# R7FA2L1AB register map
Vendor: Renesas Electronics Corporation; Series: RA2L1; File version: 0.50.00
CPU: CM23 r1p0, little endian, MPU, no FPU, VTOR, 2 interrupt priority bits, 32 interrupts
Registers are 8-bit, read-write, reset 0x0 unless marked. A register's access mark holds for its fields unless they carry their own. Offsets are from the block's base; [hi:lo] are bit positions; {n}, {i} and the like mark numbered series; 'fields as' and 'values as' point back to an identical list.

## RTC — Realtime Clock
Base 0x40044000
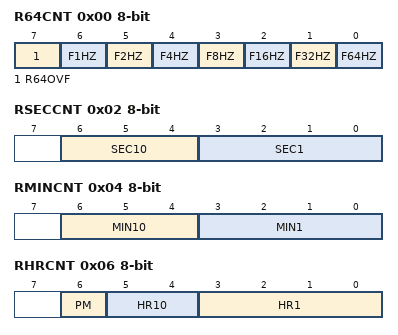
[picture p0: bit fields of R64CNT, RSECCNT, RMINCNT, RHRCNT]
0x00 R64CNT ro reset not defined — 64-Hz Counter
  [7] R64OVF
  [6] F1HZ — This bit indicates the 1-Hz state of the sub-second digit.
  [5] F2HZ — This bit indicates the 2-Hz state of the sub-second digit.
  [4] F4HZ — This bit indicates the 4-Hz state of the sub-second digit.
  [3] F8HZ — This bit indicates the 8-Hz state of the sub-second digit.
  [2] F16HZ — This bit indicates the 16-Hz state of the sub-second digit.
  [1] F32HZ — This bit indicates the 32-Hz state of the sub-second digit.
  [0] F64HZ — This bit indicates the 64-Hz state of the sub-second digit.
{0x2+2i} BCNT{i} (i=0..3) reset not defined — Binary Counter {i}
  [7:0] BCNT — Binary Counter
0x02 RSECCNT reset not defined — Second Counter (in Calendar Count Mode)
  [6:4] SEC10 — 10-Second Count
  [3:0] SEC1 — 1-Second Count
0x04 RMINCNT reset not defined — Minute Counter (in Calendar Count Mode)
  [6:4] MIN10 — 10-Minute Count
  [3:0] MIN1 — 1-Minute Count
0x06 RHRCNT reset not defined — Hour Counter (in Calendar Count Mode)
  [6] PM — AM/PM select for time counter setting.
    0=AM; 1=PM
  [5:4] HR10 — 10-Hour Count
  [3:0] HR1 — 1-Hour Count
0x08 RWKCNT reset not defined — Day-of-Week Counter (in Calendar Count Mode)
  [2:0] DAYW — Day-of-Week Counting
    0=Sunday; 1=Monday; 2=Tuesday; 3=Wednesday; 4=Thursday; 5=Friday; 6=Saturday; 7=Setting prohibited
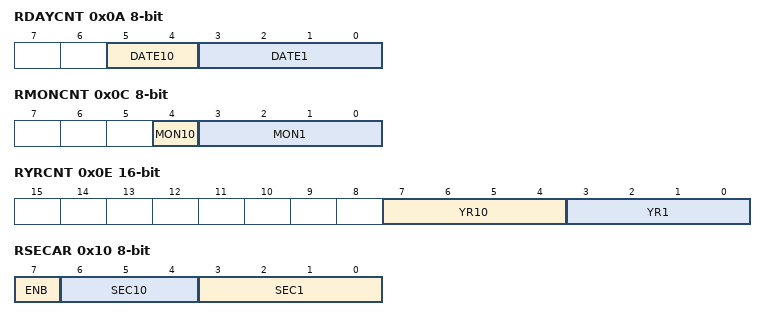
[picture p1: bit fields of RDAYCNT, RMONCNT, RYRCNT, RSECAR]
0x0A RDAYCNT (reset mask 0xC0) — Day Counter
  [5:4] DATE10 — 10-Day Count
  [3:0] DATE1 — 1-Day Count
0x0C RMONCNT (reset mask 0xE0) — Month Counter
  [4] MON10 — 10-Month Count
  [3:0] MON1 — 1-Month Count
0x0E RYRCNT 16-bit (reset mask 0xFF00) — Year Counter
  [7:4] YR10 — 10-Year Count
  [3:0] YR1 — 1-Year Count
{0x10+2i} BCNT{i}AR (i=0..3) reset not defined — Binary Counter {i} Alarm Register
  [7:0] BCNTAR — Alarm register associated with the 32-bit binary counter
0x10 RSECAR reset not defined — Second Alarm Register (in Calendar Count Mode)
  [7] ENB
    0=Do not compare register value with RSECCNT counter value; 1=Compare register value with RSECCNT counter value
  [6:4] SEC10 — 10 Seconds
  [3:0] SEC1 — 1 Second
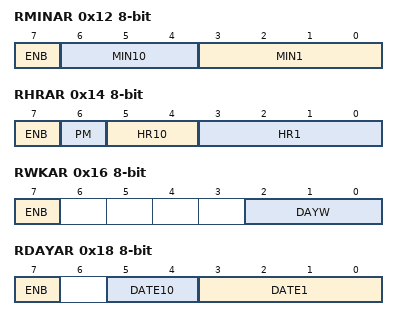
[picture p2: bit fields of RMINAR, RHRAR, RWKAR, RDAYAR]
0x12 RMINAR reset not defined — Minute Alarm Register (in Calendar Count Mode)
  [7] ENB
    0=Do not compare register value with RMINCNT counter value; 1=Compare register value with RMINCNT counter value
  [6:4] MIN10 — 10 Minutes
  [3:0] MIN1 — 1 Minute
0x14 RHRAR reset not defined — Hour Alarm Register (in Calendar Count Mode)
  [7] ENB
    0=Do not compare register value with RHRCNT counter value; 1=Compare register value with RHRCNT counter value
  [6] PM — AM/PM select for alarm setting.
    0=AM; 1=PM
  [5:4] HR10 — 10 Hours
  [3:0] HR1 — 1 Hour
0x16 RWKAR reset not defined — Day-of-Week Alarm Register (in Calendar Count Mode)
  [7] ENB
    0=Do not compare register value with RWKCNT counter value; 1=Compare register value with RWKCNT counter value
  [2:0] DAYW — Day-of-Week Setting
    values as RWKCNT.DAYW
{0x18+2i} BCNT{i}AER (i=0..1) reset not defined — Binary Counter {i} Alarm Enable Register
  [7:0] ENB — Setting the alarm enable associated with the 32-bit binary counter
0x18 RDAYAR reset not defined — Date Alarm Register (in Calendar Count Mode)
  [7] ENB
    0=Do not compare register value with RDAYCNT counter value; 1=Compare register value with RDAYCNT counter value
  [5:4] DATE10 — 10 Days
  [3:0] DATE1 — 1 Day
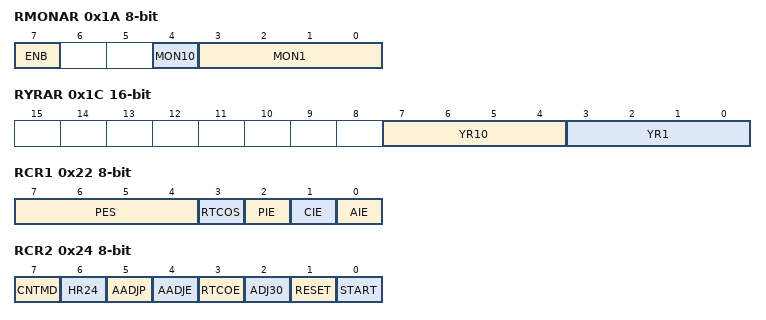
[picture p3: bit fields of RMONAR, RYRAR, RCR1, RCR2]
0x1A RMONAR reset not defined — Month Alarm Register (in Calendar Count Mode)
  [7] ENB
    0=Do not compare register value with RMONCNT counter value; 1=Compare register value with RMONCNT counter value
  [4] MON10 — 10 Months
  [3:0] MON1 — 1 Month
0x1C BCNT2AER 16-bit (reset mask 0xFF00) — Binary Counter 2 Alarm Enable Register
  [7:0] ENB — Set the alarm enable associated with the 32-bit binary counter
0x1C RYRAR 16-bit (reset mask 0xFF00) (alternate view of BCNT2AER) — Year Alarm Register (in Calendar Count Mode)
  [7:4] YR10 — 10 Years
  [3:0] YR1 — 1 Year
0x1E BCNT3AER reset not defined — Binary Counter 3 Alarm Enable Register
  fields as BCNT0AER
0x1E RYRAREN reset not defined (alternate view of BCNT3AER) — Year Alarm Enable Register (in Calendar Count Mode)
  [7] ENB
    0=Do not compare register value with RYRCNT counter value; 1=Compare register value with RYRCNT counter value
0x22 RCR1 (reset mask 0xA) — RTC Control Register 1
  [7:4] PES — Periodic Interrupt Select
    6=Generate periodic interrupt every 1/256 second; 7=Generate periodic interrupt every 1/128 second; 8=Generate periodic interrupt every 1/64 second; 9=Generate periodic interrupt every 1/32 second; 10=Generate periodic interrupt every 1/16 second; 11=Generate periodic interrupt every 1/8 second; 12=Generate periodic interrupt every 1/4 second; 13=Generate periodic interrupt every 1/2 second; 14=Generate periodic interrupt every 1 second; 15=Generate periodic interrupt every 2 seconds; other=Others (Do not generate periodic interrupts)
  [3] RTCOS — RTCOUT Output Select
    0=Outputs 1 Hz on RTCOUT; 1=Outputs 64 Hz RTCOUT
  [2] PIE — Periodic Interrupt Enable
    0=Disable periodic interrupt requests; 1=Enable periodic interrupt requests
  [1] CIE — Carry Interrupt Enable
    0=Disable carry interrupt requests; 1=Enable carry interrupt requests
  [0] AIE — Alarm Interrupt Enable
    0=Disable alarm interrupt requests; 1=Enable alarm interrupt requests
0x24 RCR2 (reset mask 0xE) — RTC Control Register 2 (in Calendar Count Mode)
  [7] CNTMD — Count Mode Select
    0=Calendar count mode; 1=Binary count mode
  [6] HR24 — Hours Mode
    0=Operate RTC in 12-hour mode; 1=Operate RTC in 24-hour mode
  [5] AADJP — Automatic Adjustment Period Select
    0=In normal operation mode, adjust RADJ.ADJ[5:0] setting from the count value of the prescaler every minute. In low-consumption clock mode, adjust RADJ.ADJ[5:0] setting from the count value of the 64-Hz counter every day.; 1=In normal operation mode, adjust RADJ.ADJ[5:0] setting from the count value of the prescaler every 10 seconds. In low-consumption clock mode, adjust RADJ.ADJ[5:0] setting from the count value of the 64-Hz counter every hour.
  [4] AADJE — Automatic Adjustment Enable
    0=Disable automatic adjustment; 1=Enable automatic adjustment
  [3] RTCOE — RTCOUT Output Enable
    0=Disable RTCOUT output; 1=Enable RTCOUT output
  [2] ADJ30 — 30-Second Adjustment
    0=In writing: Invalid (writing 0 has no effect). In reading: Normal time operation in progress, or 30-second adjustment has completed.; 1=In writing: Execute 30-second adjustment. In reading: 30-second adjustment in progress.
  [1] RESET — RTC Software Reset
    0=In writing: Invalid (writing 0 has no effect). In reading: Normal time operation in progress, or an RTC software reset has completed.; 1=In writing: Initialize the prescaler and target registers for RTC software reset. In reading: RTC software reset in progress.
  [0] START
    0=Stop prescaler and time counter; 1=Operate prescaler and time counter normally
0x24 RCR2 (reset mask 0xE) — RTC Control Register 2 (in Binary Count Mode)
  [7] CNTMD — Count Mode Select
    0=Calendar count mode; 1=Binary count mode
  [5] AADJP — Automatic Adjustment Period Select
    0=In normal operation mode, add or subtract the RADJ.ADJ[5:0] bits from the prescaler count value every 32 seconds. In low-consumption clock mode, add or subtract the RADJ.ADJ[5:0] bits from the 64-Hz counter count value every 8192 seconds.; 1=In normal operation mode, add or subtract the RADJ.ADJ[5:0] bits from the prescaler count value every 8 seconds. In low-consumption clock mode, add or subtract the RADJ.ADJ[5:0] bits from the 64-Hz counter count value every 2048 seconds.
  [4] AADJE — Automatic Adjustment Enable
    values as AADJE
  [3] RTCOE — RTCOUT Output Enable
    0=Disable RTCOUT output; 1=Enable RTCOUT output
  [1] RESET — RTC Software Reset
    values as RESET
  [0] START
    0=Stop the 32-bit binary counter, 64-Hz counter, and prescaler; 1=Operate the 32-bit binary counter, 64-Hz counter, and prescaler normally
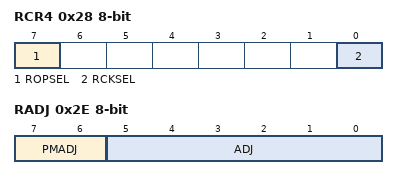
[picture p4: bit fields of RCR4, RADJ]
0x28 RCR4 (reset mask 0x7E) — RTC Control Register 4
  [7] ROPSEL — RTC Operation Mode Select
    0=Normal operation mode is selected; 1=Low-consumption clock mode is selected
  [0] RCKSEL — Count Source Select
    0=Sub-clock oscillator is selected in normal operation mode; 1=LOCO is selected in normal operation mode
0x2A RFRH 16-bit (reset mask 0xFFFE) — Frequency Register H
  [0] RFC16 — Write 0 before writing to the RFRL register after a cold start.
0x2C RFRL 16-bit reset not defined — Frequency Register L
  [15:0] RFC — Frequency Comparison Value
0x2E RADJ reset not defined — Time Error Adjustment Register
  [7:6] PMADJ — Plus-Minus
    0=Do not perform adjustment; 1=In normal operation mode, adjustment is performed by the addition to the prescaler. In low-consumption clock mode, adjustment is performed by the addition to the 64-Hz counter.; 2=In normal operation mode, adjustment is performed by the subtraction from the prescaler. In low-consumption clock mode, adjustment is performed by the subtraction from the 64-Hz counter.; 3=Setting prohibited
  [5:0] ADJ — Adjustment Value
